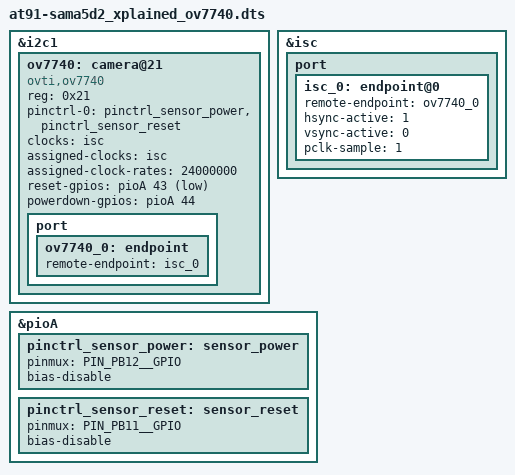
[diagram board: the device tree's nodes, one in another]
// SPDX-License-Identifier: GPL-2.0+ OR MIT
/dts-v1/;
/plugin/;

#include <dt-bindings/gpio/gpio.h>
#include "sama5d2-pinfunc.h"

&i2c1 {
	ov7740: camera@21 {
		compatible = "ovti,ov7740";
		reg = <0x21>;
		pinctrl-names = "default";
		pinctrl-0 = <&pinctrl_sensor_power &pinctrl_sensor_reset>;
		clocks = <&isc>;
		clock-names = "xvclk";
		assigned-clocks = <&isc>;
		assigned-clock-rates = <24000000>;
		reset-gpios = <&pioA 43 GPIO_ACTIVE_LOW>;
		powerdown-gpios = <&pioA 44 GPIO_ACTIVE_HIGH>;

		port {
			ov7740_0: endpoint {
				remote-endpoint = <&isc_0>;
			};
		};
	};
};

&isc {
	port {
		isc_0: endpoint@0 {
			remote-endpoint = <&ov7740_0>;
			hsync-active = <1>;
			vsync-active = <0>;
			pclk-sample = <1>;
		};
	};
};

&pioA {
	pinctrl_sensor_power: sensor_power {
		pinmux = <PIN_PB12__GPIO>;
		bias-disable;
	};

	pinctrl_sensor_reset: sensor_reset {
		pinmux = <PIN_PB11__GPIO>;
		bias-disable;
	};
};
